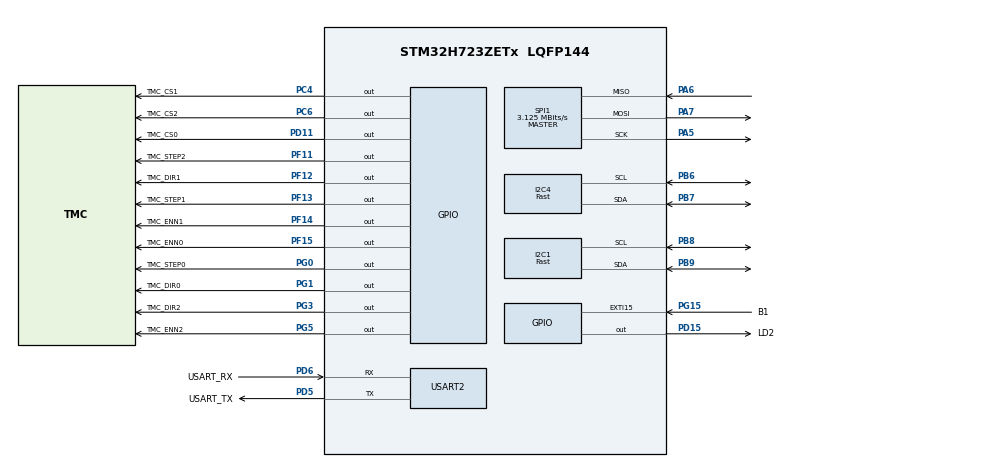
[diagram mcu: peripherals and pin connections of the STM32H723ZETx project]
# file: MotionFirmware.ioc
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Dma.Request0=USART2_RX
Dma.Request1=USART2_TX
Dma.USART2_RX.0.Direction=DMA_PERIPH_TO_MEMORY
Dma.USART2_RX.0.EventEnable=DISABLE
Dma.USART2_RX.0.FIFOMode=DMA_FIFOMODE_DISABLE
Dma.USART2_RX.0.Instance=DMA1_Stream0
Dma.USART2_RX.0.MemDataAlignment=DMA_MDATAALIGN_BYTE
Dma.USART2_RX.0.MemInc=DMA_MINC_ENABLE
Dma.USART2_RX.0.Mode=DMA_CIRCULAR
Dma.USART2_RX.0.PeriphDataAlignment=DMA_PDATAALIGN_BYTE
Dma.USART2_RX.0.PeriphInc=DMA_PINC_DISABLE
Dma.USART2_RX.0.Polarity=HAL_DMAMUX_REQ_GEN_RISING
Dma.USART2_RX.0.Priority=DMA_PRIORITY_LOW
Dma.USART2_RX.0.RequestNumber=1
Dma.USART2_RX.0.SignalID=NONE
Dma.USART2_RX.0.SyncEnable=DISABLE
Dma.USART2_RX.0.SyncPolarity=HAL_DMAMUX_SYNC_NO_EVENT
Dma.USART2_RX.0.SyncRequestNumber=1
Dma.USART2_RX.0.SyncSignalID=NONE
Dma.USART2_TX.1.Direction=DMA_MEMORY_TO_PERIPH
Dma.USART2_TX.1.EventEnable=DISABLE
Dma.USART2_TX.1.FIFOMode=DMA_FIFOMODE_DISABLE
Dma.USART2_TX.1.Instance=DMA1_Stream1
Dma.USART2_TX.1.MemDataAlignment=DMA_MDATAALIGN_BYTE
Dma.USART2_TX.1.MemInc=DMA_MINC_ENABLE
Dma.USART2_TX.1.Mode=DMA_NORMAL
Dma.USART2_TX.1.PeriphDataAlignment=DMA_PDATAALIGN_BYTE
Dma.USART2_TX.1.PeriphInc=DMA_PINC_DISABLE
Dma.USART2_TX.1.Polarity=HAL_DMAMUX_REQ_GEN_RISING
Dma.USART2_TX.1.Priority=DMA_PRIORITY_LOW
Dma.USART2_TX.1.RequestNumber=1
Dma.USART2_TX.1.SignalID=NONE
Dma.USART2_TX.1.SyncEnable=DISABLE
Dma.USART2_TX.1.SyncPolarity=HAL_DMAMUX_SYNC_NO_EVENT
Dma.USART2_TX.1.SyncRequestNumber=1
Dma.USART2_TX.1.SyncSignalID=NONE
I2C1.I2C_Speed_Mode=I2C_Fast
I2C1.Timing=0x10C0ECFF
I2C4.I2C_Speed_Mode=I2C_Fast
I2C4.Timing=0x10C0ECFF
Mcu.Family=STM32H7
Mcu.Name=STM32H723ZETx
Mcu.Package=LQFP144
NVIC.DMA1_Stream0_IRQn=true\:5\:0\:false\:false\:true\:false\:true\:true
NVIC.DMA1_Stream1_IRQn=true\:5\:0\:false\:false\:true\:false\:true\:true
NVIC.EXTI15_10_IRQn=true\:15\:0\:false\:false\:true\:false\:true\:true
NVIC.PriorityGroup=NVIC_PRIORITYGROUP_4
NVIC.TIM2_IRQn=true\:0\:0\:false\:false\:true\:true\:true\:true
NVIC.TIM5_IRQn=true\:0\:0\:false\:false\:true\:true\:true\:true
NVIC.USART2_IRQn=true\:5\:0\:false\:false\:true\:true\:true\:true
PA13(JTMS/SWDIO).GPIO_Label=TMS
PA13(JTMS/SWDIO).Mode=Serial_Wire
PA13(JTMS/SWDIO).Signal=DEBUG_JTMS-SWDIO
PA14(JTCK/SWCLK).GPIO_Label=TCK
PA14(JTCK/SWCLK).Mode=Serial_Wire
PA14(JTCK/SWCLK).Signal=DEBUG_JTCK-SWCLK
PA5.GPIO_Speed=GPIO_SPEED_FREQ_VERY_HIGH
PA5.Mode=Full_Duplex_Master
PA5.Signal=SPI1_SCK
PA6.GPIO_PuPd=GPIO_PULLUP
PA6.GPIO_Speed=GPIO_SPEED_FREQ_VERY_HIGH
PA6.Mode=Full_Duplex_Master
PA6.Signal=SPI1_MISO
PA7.GPIO_Speed=GPIO_SPEED_FREQ_VERY_HIGH
PA7.Mode=Full_Duplex_Master
PA7.Signal=SPI1_MOSI
PB6.GPIO_PuPd=GPIO_PULLUP
PB6.Mode=I2C
PB6.Signal=I2C4_SCL
PB7.GPIO_PuPd=GPIO_PULLUP
PB7.Mode=I2C
PB7.Signal=I2C4_SDA
PB8.GPIO_PuPd=GPIO_PULLUP
PB8.Mode=I2C
PB8.Signal=I2C1_SCL
PB9.GPIO_PuPd=GPIO_PULLUP
PB9.Mode=I2C
PB9.Signal=I2C1_SDA
PC14-OSC32_IN.Mode=LSE-External-Oscillator
PC14-OSC32_IN.Signal=RCC_OSC32_IN
PC15-OSC32_OUT.Mode=LSE-External-Oscillator
PC15-OSC32_OUT.Signal=RCC_OSC32_OUT
PC4.GPIO_Label=TMC_CS1
PC4.GPIO_PuPd=GPIO_PULLUP
PC4.GPIO_Speed=GPIO_SPEED_FREQ_HIGH
PC4.PinState=GPIO_PIN_SET
PC4.Signal=GPIO_Output
PC6.GPIO_Label=TMC_CS2
PC6.GPIO_PuPd=GPIO_PULLUP
PC6.GPIO_Speed=GPIO_SPEED_FREQ_HIGH
PC6.PinState=GPIO_PIN_SET
PC6.Signal=GPIO_Output
PD11.GPIO_Label=TMC_CS0
PD11.GPIO_PuPd=GPIO_PULLUP
PD11.GPIO_Speed=GPIO_SPEED_FREQ_HIGH
PD11.PinState=GPIO_PIN_SET
PD11.Signal=GPIO_Output
PD15.GPIO_Label=LD2
PD15.Signal=GPIO_Output
PD5.GPIO_Label=USART_TX
PD5.GPIO_PuPd=GPIO_PULLUP
PD5.Mode=Asynchronous
PD5.Signal=USART2_TX
PD6.GPIO_Label=USART_RX
PD6.GPIO_PuPd=GPIO_PULLUP
PD6.Mode=Asynchronous
PD6.Signal=USART2_RX
PF11.GPIO_Label=TMC_STEP2
PF11.GPIO_Speed=GPIO_SPEED_FREQ_VERY_HIGH
PF11.Signal=GPIO_Output
PF12.GPIO_Label=TMC_DIR1
PF12.GPIO_Speed=GPIO_SPEED_FREQ_VERY_HIGH
PF12.Signal=GPIO_Output
PF13.GPIO_Label=TMC_STEP1
PF13.GPIO_Speed=GPIO_SPEED_FREQ_VERY_HIGH
PF13.Signal=GPIO_Output
PF14.GPIO_Label=TMC_ENN1
PF14.GPIO_PuPd=GPIO_PULLUP
PF14.GPIO_Speed=GPIO_SPEED_FREQ_HIGH
PF14.PinState=GPIO_PIN_SET
PF14.Signal=GPIO_Output
PF15.GPIO_Label=TMC_ENN0
PF15.GPIO_PuPd=GPIO_PULLUP
PF15.GPIO_Speed=GPIO_SPEED_FREQ_HIGH
PF15.PinState=GPIO_PIN_SET
PF15.Signal=GPIO_Output
PG0.GPIO_Label=TMC_STEP0
PG0.GPIO_Speed=GPIO_SPEED_FREQ_VERY_HIGH
PG0.Signal=GPIO_Output
PG1.GPIO_Label=TMC_DIR0
PG1.GPIO_Speed=GPIO_SPEED_FREQ_VERY_HIGH
PG1.Signal=GPIO_Output
PG3.GPIO_Label=TMC_DIR2
PG3.GPIO_Speed=GPIO_SPEED_FREQ_VERY_HIGH
PG3.Signal=GPIO_Output
PG5.GPIO_Label=TMC_ENN2
PG5.GPIO_PuPd=GPIO_PULLUP
PG5.GPIO_Speed=GPIO_SPEED_FREQ_HIGH
PG5.PinState=GPIO_PIN_SET
PG5.Signal=GPIO_Output
PG15.GPIO_Label=B1
PG15.GPIO_ModeDefaultEXTI=GPIO_MODE_IT_FALLING
PG15.GPIO_PuPd=GPIO_PULLUP
PG15.Signal=GPXTI15
PH0-OSC_IN.Mode=HSE-External-Oscillator
PH0-OSC_IN.Signal=RCC_OSC_IN
PH1-OSC_OUT.Mode=HSE-External-Oscillator
PH1-OSC_OUT.Signal=RCC_OSC_OUT
ProjectManager.HeapSize=0x800
ProjectManager.StackSize=0x1000
ProjectManager.TargetToolchain=CMake
RCC.ADCFreq_Value=50390625
RCC.APB1Freq_Value=100000000
RCC.APB2Freq_Value=100000000
RCC.APB3Freq_Value=100000000
RCC.APB4Freq_Value=100000000
RCC.CortexFreq_Value=400000000
RCC.D1PPRE=RCC_APB3_DIV2
RCC.D2PPRE1=RCC_APB1_DIV2
RCC.D2PPRE2=RCC_APB2_DIV2
RCC.D3PPRE=RCC_APB4_DIV2
RCC.DIVM1=5
RCC.DIVN1=160
RCC.DIVP1=2
RCC.DIVQ1=8
RCC.DIVR1=2
RCC.FLatency=FLASH_LATENCY_2
RCC.HCLKFreq_Value=200000000
RCC.HPRE=RCC_HCLK_DIV2
RCC.HSE_VALUE=25000000
RCC.PLLFRACN=0
RCC.PLLSourceVirtual=RCC_PLLSOURCE_HSE
RCC.PWR_Regulator_Voltage_Scale=PWR_REGULATOR_VOLTAGE_SCALE1
RCC.SYSCLKFreq_VALUE=400000000
RCC.SYSCLKSource=RCC_SYSCLKSOURCE_PLLCLK
RCC.SupplySource=PWR_LDO_SUPPLY
RCC.USBFreq_Value=100000000
SPI1.BaudRatePrescaler=SPI_BAUDRATEPRESCALER_32
SPI1.CLKPhase=SPI_PHASE_2EDGE
SPI1.CLKPolarity=SPI_POLARITY_HIGH
SPI1.CalculateBaudRate=3.125 MBits/s
SPI1.DataSize=SPI_DATASIZE_8BIT
SPI1.Direction=SPI_DIRECTION_2LINES
SPI1.MasterKeepIOState=SPI_MASTER_KEEP_IO_STATE_ENABLE
SPI1.Mode=SPI_MODE_MASTER
SPI1.NSSPMode=SPI_NSS_PULSE_DISABLE
SPI1.VirtualType=VM_MASTER
TIM2.AutoReloadPreload=TIM_AUTORELOAD_PRELOAD_DISABLE
TIM2.Period=4294967295
TIM2.Prescaler=199
TIM5.AutoReloadPreload=TIM_AUTORELOAD_PRELOAD_DISABLE
TIM5.Period=4294967295
TIM5.Prescaler=199
USART2.VirtualMode-Asynchronous=VM_ASYNC
VP_TIM2_VS_ClockSourceINT.Mode=Internal
VP_TIM5_VS_ClockSourceINT.Mode=Internal
board=custom

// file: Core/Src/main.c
/* USER CODE BEGIN Header */
/**
  ******************************************************************************
  * @file           : main.c
  * @brief          : Main program body
  ******************************************************************************
  * @attention
  *
  * Copyright (c) 2026 STMicroelectronics.
  * All rights reserved.
  *
  * This software is licensed under terms that can be found in the LICENSE file
  * in the root directory of this software component.
  * If no LICENSE file comes with this software, it is provided AS-IS.
  *
  ******************************************************************************
  */
/* USER CODE END Header */
#include "main.h"

/* USER CODE BEGIN Includes */
#include "fw_app.h"
/* USER CODE END Includes */

I2C_HandleTypeDef hi2c1;
I2C_HandleTypeDef hi2c4;

SPI_HandleTypeDef hspi1;

TIM_HandleTypeDef htim2;
TIM_HandleTypeDef htim5;

UART_HandleTypeDef huart2;
DMA_HandleTypeDef hdma_usart2_rx;
DMA_HandleTypeDef hdma_usart2_tx;

void SystemClock_Config(void);
static void MX_GPIO_Init(void);
static void MX_DMA_Init(void);
static void MX_I2C1_Init(void);
static void MX_I2C4_Init(void);
static void MX_SPI1_Init(void);
static void MX_TIM2_Init(void);
static void MX_TIM5_Init(void);
static void MX_USART2_UART_Init(void);

int main(void)
{

  /* MCU Configuration--------------------------------------------------------*/

  /* Reset of all peripherals, Initializes the Flash interface and the Systick. */
  HAL_Init();

  /* Configure the system clock */
  SystemClock_Config();

  /* Initialize all configured peripherals */
  MX_GPIO_Init();
  MX_DMA_Init();
  MX_I2C1_Init();
  MX_I2C4_Init();
  MX_SPI1_Init();
  MX_TIM2_Init();
  MX_TIM5_Init();
  MX_USART2_UART_Init();
  /* USER CODE BEGIN 2 */
  fw_app_init();
  /* USER CODE END 2 */

  /* Infinite loop */
  while (1)
  {

    /* USER CODE BEGIN 3 */
    fw_app_poll();
  }
  /* USER CODE END 3 */
}

void SystemClock_Config(void)
{
  RCC_OscInitTypeDef RCC_OscInitStruct = {0};
  RCC_ClkInitTypeDef RCC_ClkInitStruct = {0};

  /** Supply configuration update enable
  */
  HAL_PWREx_ConfigSupply(PWR_LDO_SUPPLY);

  /** Configure the main internal regulator output voltage
  */
  __HAL_PWR_VOLTAGESCALING_CONFIG(PWR_REGULATOR_VOLTAGE_SCALE1);

  while(!__HAL_PWR_GET_FLAG(PWR_FLAG_VOSRDY)) {}

  /** Initializes the RCC Oscillators according to the specified parameters
  * in the RCC_OscInitTypeDef structure.
  */
  RCC_OscInitStruct.OscillatorType = RCC_OSCILLATORTYPE_HSE;
  RCC_OscInitStruct.HSEState = RCC_HSE_ON;
  RCC_OscInitStruct.PLL.PLLState = RCC_PLL_ON;
  RCC_OscInitStruct.PLL.PLLSource = RCC_PLLSOURCE_HSE;
  RCC_OscInitStruct.PLL.PLLM = 5;
  RCC_OscInitStruct.PLL.PLLN = 160;
  RCC_OscInitStruct.PLL.PLLP = 2;
  RCC_OscInitStruct.PLL.PLLQ = 8;
  RCC_OscInitStruct.PLL.PLLR = 2;
  RCC_OscInitStruct.PLL.PLLRGE = RCC_PLL1VCIRANGE_2;
  RCC_OscInitStruct.PLL.PLLVCOSEL = RCC_PLL1VCOWIDE;
  RCC_OscInitStruct.PLL.PLLFRACN = 0;
  if (HAL_RCC_OscConfig(&RCC_OscInitStruct) != HAL_OK)
  {
    Error_Handler();
  }

  /** Initializes the CPU, AHB and APB buses clocks
  */
  RCC_ClkInitStruct.ClockType = RCC_CLOCKTYPE_HCLK|RCC_CLOCKTYPE_SYSCLK
                              |RCC_CLOCKTYPE_PCLK1|RCC_CLOCKTYPE_PCLK2
                              |RCC_CLOCKTYPE_D3PCLK1|RCC_CLOCKTYPE_D1PCLK1;
  RCC_ClkInitStruct.SYSCLKSource = RCC_SYSCLKSOURCE_PLLCLK;
  RCC_ClkInitStruct.SYSCLKDivider = RCC_SYSCLK_DIV1;
  RCC_ClkInitStruct.AHBCLKDivider = RCC_HCLK_DIV2;
  RCC_ClkInitStruct.APB3CLKDivider = RCC_APB3_DIV2;
  RCC_ClkInitStruct.APB1CLKDivider = RCC_APB1_DIV2;
  RCC_ClkInitStruct.APB2CLKDivider = RCC_APB2_DIV2;
  RCC_ClkInitStruct.APB4CLKDivider = RCC_APB4_DIV2;

  if (HAL_RCC_ClockConfig(&RCC_ClkInitStruct, FLASH_LATENCY_2) != HAL_OK)
  {
    Error_Handler();
  }
}

static void MX_I2C1_Init(void)
{

  hi2c1.Instance = I2C1;
  hi2c1.Init.Timing = 0x10C0ECFF;
  hi2c1.Init.OwnAddress1 = 0;
  hi2c1.Init.AddressingMode = I2C_ADDRESSINGMODE_7BIT;
  hi2c1.Init.DualAddressMode = I2C_DUALADDRESS_DISABLE;
  hi2c1.Init.OwnAddress2 = 0;
  hi2c1.Init.OwnAddress2Masks = I2C_OA2_NOMASK;
  hi2c1.Init.GeneralCallMode = I2C_GENERALCALL_DISABLE;
  hi2c1.Init.NoStretchMode = I2C_NOSTRETCH_DISABLE;
  if (HAL_I2C_Init(&hi2c1) != HAL_OK)
  {
    Error_Handler();
  }

  /** Configure Analogue filter
  */
  if (HAL_I2CEx_ConfigAnalogFilter(&hi2c1, I2C_ANALOGFILTER_ENABLE) != HAL_OK)
  {
    Error_Handler();
  }

  /** Configure Digital filter
  */
  if (HAL_I2CEx_ConfigDigitalFilter(&hi2c1, 0) != HAL_OK)
  {
    Error_Handler();
  }

}

static void MX_I2C4_Init(void)
{

  hi2c4.Instance = I2C4;
  hi2c4.Init.Timing = 0x10C0ECFF;
  hi2c4.Init.OwnAddress1 = 0;
  hi2c4.Init.AddressingMode = I2C_ADDRESSINGMODE_7BIT;
  hi2c4.Init.DualAddressMode = I2C_DUALADDRESS_DISABLE;
  hi2c4.Init.OwnAddress2 = 0;
  hi2c4.Init.OwnAddress2Masks = I2C_OA2_NOMASK;
  hi2c4.Init.GeneralCallMode = I2C_GENERALCALL_DISABLE;
  hi2c4.Init.NoStretchMode = I2C_NOSTRETCH_DISABLE;
  if (HAL_I2C_Init(&hi2c4) != HAL_OK)
  {
    Error_Handler();
  }

  /** Configure Analogue filter
  */
  if (HAL_I2CEx_ConfigAnalogFilter(&hi2c4, I2C_ANALOGFILTER_ENABLE) != HAL_OK)
  {
    Error_Handler();
  }

  /** Configure Digital filter
  */
  if (HAL_I2CEx_ConfigDigitalFilter(&hi2c4, 0) != HAL_OK)
  {
    Error_Handler();
  }

}

static void MX_SPI1_Init(void)
{

  /* SPI1 parameter configuration*/
  hspi1.Instance = SPI1;
  hspi1.Init.Mode = SPI_MODE_MASTER;
  hspi1.Init.Direction = SPI_DIRECTION_2LINES;
  hspi1.Init.DataSize = SPI_DATASIZE_8BIT;
  hspi1.Init.CLKPolarity = SPI_POLARITY_HIGH;
  hspi1.Init.CLKPhase = SPI_PHASE_2EDGE;
  hspi1.Init.NSS = SPI_NSS_SOFT;
  hspi1.Init.BaudRatePrescaler = SPI_BAUDRATEPRESCALER_32;
  hspi1.Init.FirstBit = SPI_FIRSTBIT_MSB;
  hspi1.Init.TIMode = SPI_TIMODE_DISABLE;
  hspi1.Init.CRCCalculation = SPI_CRCCALCULATION_DISABLE;
  hspi1.Init.CRCPolynomial = 0x0;
  hspi1.Init.NSSPMode = SPI_NSS_PULSE_DISABLE;
  hspi1.Init.NSSPolarity = SPI_NSS_POLARITY_LOW;
  hspi1.Init.FifoThreshold = SPI_FIFO_THRESHOLD_01DATA;
  hspi1.Init.TxCRCInitializationPattern = SPI_CRC_INITIALIZATION_ALL_ZERO_PATTERN;
  hspi1.Init.RxCRCInitializationPattern = SPI_CRC_INITIALIZATION_ALL_ZERO_PATTERN;
  hspi1.Init.MasterSSIdleness = SPI_MASTER_SS_IDLENESS_00CYCLE;
  hspi1.Init.MasterInterDataIdleness = SPI_MASTER_INTERDATA_IDLENESS_00CYCLE;
  hspi1.Init.MasterReceiverAutoSusp = SPI_MASTER_RX_AUTOSUSP_DISABLE;
  hspi1.Init.MasterKeepIOState = SPI_MASTER_KEEP_IO_STATE_ENABLE;
  hspi1.Init.IOSwap = SPI_IO_SWAP_DISABLE;
  if (HAL_SPI_Init(&hspi1) != HAL_OK)
  {
    Error_Handler();
  }

}

static void MX_TIM2_Init(void)
{

  TIM_ClockConfigTypeDef sClockSourceConfig = {0};
  TIM_MasterConfigTypeDef sMasterConfig = {0};

  htim2.Instance = TIM2;
  htim2.Init.Prescaler = 199;
  htim2.Init.CounterMode = TIM_COUNTERMODE_UP;
  htim2.Init.Period = 4294967295;
  htim2.Init.ClockDivision = TIM_CLOCKDIVISION_DIV1;
  htim2.Init.AutoReloadPreload = TIM_AUTORELOAD_PRELOAD_DISABLE;
  if (HAL_TIM_Base_Init(&htim2) != HAL_OK)
  {
    Error_Handler();
  }
  sClockSourceConfig.ClockSource = TIM_CLOCKSOURCE_INTERNAL;
  if (HAL_TIM_ConfigClockSource(&htim2, &sClockSourceConfig) != HAL_OK)
  {
    Error_Handler();
  }
  sMasterConfig.MasterOutputTrigger = TIM_TRGO_RESET;
  sMasterConfig.MasterSlaveMode = TIM_MASTERSLAVEMODE_DISABLE;
  if (HAL_TIMEx_MasterConfigSynchronization(&htim2, &sMasterConfig) != HAL_OK)
  {
    Error_Handler();
  }

}

static void MX_TIM5_Init(void)
{

  TIM_ClockConfigTypeDef sClockSourceConfig = {0};
  TIM_MasterConfigTypeDef sMasterConfig = {0};

  htim5.Instance = TIM5;
  htim5.Init.Prescaler = 199;
  htim5.Init.CounterMode = TIM_COUNTERMODE_UP;
  htim5.Init.Period = 4294967295;
  htim5.Init.ClockDivision = TIM_CLOCKDIVISION_DIV1;
  htim5.Init.AutoReloadPreload = TIM_AUTORELOAD_PRELOAD_DISABLE;
  if (HAL_TIM_Base_Init(&htim5) != HAL_OK)
  {
    Error_Handler();
  }
  sClockSourceConfig.ClockSource = TIM_CLOCKSOURCE_INTERNAL;
  if (HAL_TIM_ConfigClockSource(&htim5, &sClockSourceConfig) != HAL_OK)
  {
    Error_Handler();
  }
  sMasterConfig.MasterOutputTrigger = TIM_TRGO_RESET;
  sMasterConfig.MasterSlaveMode = TIM_MASTERSLAVEMODE_DISABLE;
  if (HAL_TIMEx_MasterConfigSynchronization(&htim5, &sMasterConfig) != HAL_OK)
  {
    Error_Handler();
  }

}

static void MX_USART2_UART_Init(void)
{

  huart2.Instance = USART2;
  huart2.Init.BaudRate = 115200;
  huart2.Init.WordLength = UART_WORDLENGTH_8B;
  huart2.Init.StopBits = UART_STOPBITS_1;
  huart2.Init.Parity = UART_PARITY_NONE;
  huart2.Init.Mode = UART_MODE_TX_RX;
  huart2.Init.HwFlowCtl = UART_HWCONTROL_NONE;
  huart2.Init.OverSampling = UART_OVERSAMPLING_16;
  huart2.Init.OneBitSampling = UART_ONE_BIT_SAMPLE_DISABLE;
  huart2.Init.ClockPrescaler = UART_PRESCALER_DIV1;
  huart2.AdvancedInit.AdvFeatureInit = UART_ADVFEATURE_NO_INIT;
  if (HAL_UART_Init(&huart2) != HAL_OK)
  {
    Error_Handler();
  }
  if (HAL_UARTEx_SetTxFifoThreshold(&huart2, UART_TXFIFO_THRESHOLD_1_8) != HAL_OK)
  {
    Error_Handler();
  }
  if (HAL_UARTEx_SetRxFifoThreshold(&huart2, UART_RXFIFO_THRESHOLD_1_8) != HAL_OK)
  {
    Error_Handler();
  }
  if (HAL_UARTEx_DisableFifoMode(&huart2) != HAL_OK)
  {
    Error_Handler();
  }

}

static void MX_DMA_Init(void)
{

  /* DMA controller clock enable */
  __HAL_RCC_DMA1_CLK_ENABLE();

  /* DMA interrupt init */
  /* DMA1_Stream0_IRQn interrupt configuration */
  HAL_NVIC_SetPriority(DMA1_Stream0_IRQn, 5, 0);
  HAL_NVIC_EnableIRQ(DMA1_Stream0_IRQn);
  /* DMA1_Stream1_IRQn interrupt configuration */
  HAL_NVIC_SetPriority(DMA1_Stream1_IRQn, 5, 0);
  HAL_NVIC_EnableIRQ(DMA1_Stream1_IRQn);

}

static void MX_GPIO_Init(void)
{
  GPIO_InitTypeDef GPIO_InitStruct = {0};

  /* GPIO Ports Clock Enable */
  __HAL_RCC_GPIOC_CLK_ENABLE();
  __HAL_RCC_GPIOH_CLK_ENABLE();
  __HAL_RCC_GPIOA_CLK_ENABLE();
  __HAL_RCC_GPIOF_CLK_ENABLE();
  __HAL_RCC_GPIOG_CLK_ENABLE();
  __HAL_RCC_GPIOD_CLK_ENABLE();
  __HAL_RCC_GPIOB_CLK_ENABLE();

  /*Configure GPIO pin Output Level */
  HAL_GPIO_WritePin(GPIOC, TMC_CS1_Pin|TMC_CS2_Pin, GPIO_PIN_SET);

  /*Configure GPIO pin Output Level */
  HAL_GPIO_WritePin(GPIOF, TMC_STEP2_Pin|TMC_DIR1_Pin|TMC_STEP1_Pin, GPIO_PIN_RESET);

  /*Configure GPIO pin Output Level */
  HAL_GPIO_WritePin(GPIOF, TMC_ENN1_Pin|TMC_ENN0_Pin, GPIO_PIN_SET);

  /*Configure GPIO pin Output Level */
  HAL_GPIO_WritePin(GPIOG, TMC_STEP0_Pin|TMC_DIR0_Pin|TMC_DIR2_Pin, GPIO_PIN_RESET);

  /*Configure GPIO pin Output Level */
  HAL_GPIO_WritePin(TMC_ENN2_GPIO_Port, TMC_ENN2_Pin, GPIO_PIN_SET);

  /*Configure GPIO pin Output Level */
  HAL_GPIO_WritePin(TMC_CS0_GPIO_Port, TMC_CS0_Pin, GPIO_PIN_SET);

  /*Configure GPIO pin Output Level */
  HAL_GPIO_WritePin(LD2_GPIO_Port, LD2_Pin, GPIO_PIN_RESET);

  /*Configure GPIO pins : TMC_CS1_Pin TMC_CS2_Pin */
  GPIO_InitStruct.Pin = TMC_CS1_Pin|TMC_CS2_Pin;
  GPIO_InitStruct.Mode = GPIO_MODE_OUTPUT_PP;
  GPIO_InitStruct.Pull = GPIO_PULLUP;
  GPIO_InitStruct.Speed = GPIO_SPEED_FREQ_HIGH;
  HAL_GPIO_Init(GPIOC, &GPIO_InitStruct);

  /*Configure GPIO pins : TMC_STEP2_Pin TMC_DIR1_Pin TMC_STEP1_Pin */
  GPIO_InitStruct.Pin = TMC_STEP2_Pin|TMC_DIR1_Pin|TMC_STEP1_Pin;
  GPIO_InitStruct.Mode = GPIO_MODE_OUTPUT_PP;
  GPIO_InitStruct.Pull = GPIO_NOPULL;
  GPIO_InitStruct.Speed = GPIO_SPEED_FREQ_VERY_HIGH;
  HAL_GPIO_Init(GPIOF, &GPIO_InitStruct);

  /*Configure GPIO pins : TMC_ENN1_Pin TMC_ENN0_Pin */
  GPIO_InitStruct.Pin = TMC_ENN1_Pin|TMC_ENN0_Pin;
  GPIO_InitStruct.Mode = GPIO_MODE_OUTPUT_PP;
  GPIO_InitStruct.Pull = GPIO_PULLUP;
  GPIO_InitStruct.Speed = GPIO_SPEED_FREQ_HIGH;
  HAL_GPIO_Init(GPIOF, &GPIO_InitStruct);

  /*Configure GPIO pins : TMC_STEP0_Pin TMC_DIR0_Pin TMC_DIR2_Pin */
  GPIO_InitStruct.Pin = TMC_STEP0_Pin|TMC_DIR0_Pin|TMC_DIR2_Pin;
  GPIO_InitStruct.Mode = GPIO_MODE_OUTPUT_PP;
  GPIO_InitStruct.Pull = GPIO_NOPULL;
  GPIO_InitStruct.Speed = GPIO_SPEED_FREQ_VERY_HIGH;
  HAL_GPIO_Init(GPIOG, &GPIO_InitStruct);

  /*Configure GPIO pin : TMC_ENN2_Pin */
  GPIO_InitStruct.Pin = TMC_ENN2_Pin;
  GPIO_InitStruct.Mode = GPIO_MODE_OUTPUT_PP;
  GPIO_InitStruct.Pull = GPIO_PULLUP;
  GPIO_InitStruct.Speed = GPIO_SPEED_FREQ_HIGH;
  HAL_GPIO_Init(TMC_ENN2_GPIO_Port, &GPIO_InitStruct);

  /*Configure GPIO pin : TMC_CS0_Pin */
  GPIO_InitStruct.Pin = TMC_CS0_Pin;
  GPIO_InitStruct.Mode = GPIO_MODE_OUTPUT_PP;
  GPIO_InitStruct.Pull = GPIO_PULLUP;
  GPIO_InitStruct.Speed = GPIO_SPEED_FREQ_HIGH;
  HAL_GPIO_Init(TMC_CS0_GPIO_Port, &GPIO_InitStruct);

  /*Configure GPIO pin : LD2_Pin */
  GPIO_InitStruct.Pin = LD2_Pin;
  GPIO_InitStruct.Mode = GPIO_MODE_OUTPUT_PP;
  GPIO_InitStruct.Pull = GPIO_NOPULL;
  GPIO_InitStruct.Speed = GPIO_SPEED_FREQ_LOW;
  HAL_GPIO_Init(LD2_GPIO_Port, &GPIO_InitStruct);

  /*Configure GPIO pin : B1_Pin */
  GPIO_InitStruct.Pin = B1_Pin;
  GPIO_InitStruct.Mode = GPIO_MODE_IT_FALLING;
  GPIO_InitStruct.Pull = GPIO_PULLUP;
  HAL_GPIO_Init(B1_GPIO_Port, &GPIO_InitStruct);

  /* EXTI interrupt init*/
  HAL_NVIC_SetPriority(B1_EXTI_IRQn, 15, 0);
  HAL_NVIC_EnableIRQ(B1_EXTI_IRQn);

}

void Error_Handler(void)
{
  /* USER CODE BEGIN Error_Handler_Debug */
  /* User can add his own implementation to report the HAL error return state */
  __disable_irq();
  TMC_STEP0_GPIO_Port->BSRR = (uint32_t)TMC_STEP0_Pin << 16U;
  TMC_STEP1_GPIO_Port->BSRR = (uint32_t)TMC_STEP1_Pin << 16U;
  TMC_STEP2_GPIO_Port->BSRR = (uint32_t)TMC_STEP2_Pin << 16U;
  fw_app_error_handler();
  while (1)
  {
    HAL_GPIO_TogglePin(LD2_GPIO_Port, LD2_Pin);
    for (volatile uint32_t i = 0; i < 2000000U; i++)
    {
      __NOP();
    }
  }
  /* USER CODE END Error_Handler_Debug */
}
